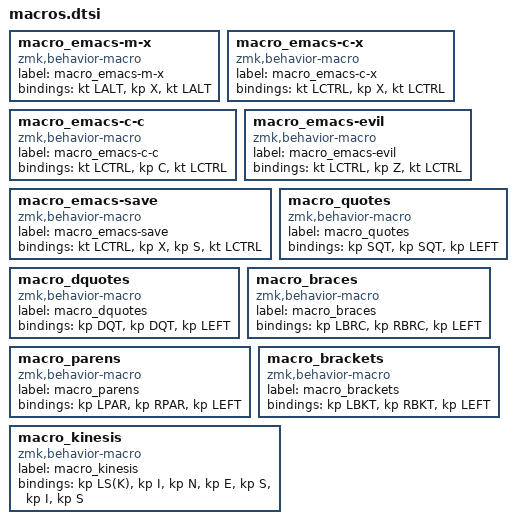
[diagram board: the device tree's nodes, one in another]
macro_emacs-m-x: macro_emacs-m-x{
compatible = "zmk,behavior-macro";
label = "macro_emacs-m-x";
#binding-cells = <0>;
bindings = <&kt LALT>, <&kp X>, <&kt LALT>;
};
macro_emacs-c-x: macro_emacs-c-x{
compatible = "zmk,behavior-macro";
label = "macro_emacs-c-x";
#binding-cells = <0>;
bindings = <&kt LCTRL>, <&kp X>, <&kt LCTRL>;
};
macro_emacs-c-c: macro_emacs-c-c{
compatible = "zmk,behavior-macro";
label = "macro_emacs-c-c";
#binding-cells = <0>;
bindings = <&kt LCTRL>, <&kp C>, <&kt LCTRL>;
};
macro_emacs-evil: macro_emacs-evil{
compatible = "zmk,behavior-macro";
label = "macro_emacs-evil";
#binding-cells = <0>;
bindings = <&kt LCTRL>, <&kp Z>, <&kt LCTRL>;
};
macro_emacs-save: macro_emacs-save{
compatible = "zmk,behavior-macro";
label = "macro_emacs-save";
#binding-cells = <0>;
bindings = <&kt LCTRL>, <&kp X>, <&kp S>, <&kt LCTRL>;
};
macro_quotes: macro_quotes{
compatible = "zmk,behavior-macro";
label = "macro_quotes";
#binding-cells = <0>;
bindings = <&kp SQT>, <&kp SQT>, <&kp LEFT>;
};
macro_dquotes: macro_dquotes{
compatible = "zmk,behavior-macro";
label = "macro_dquotes";
#binding-cells = <0>;
bindings = <&kp DQT>, <&kp DQT>, <&kp LEFT>;
};
macro_braces: macro_braces{
compatible = "zmk,behavior-macro";
label = "macro_braces";
#binding-cells = <0>;
bindings = <&kp LBRC>, <&kp RBRC>, <&kp LEFT>;
};
macro_parens: macro_parens{
compatible = "zmk,behavior-macro";
label = "macro_parens";
#binding-cells = <0>;
bindings = <&kp LPAR>, <&kp RPAR>, <&kp LEFT>;
};
macro_brackets: macro_brackets{
compatible = "zmk,behavior-macro";
label = "macro_brackets";
#binding-cells = <0>;
bindings = <&kp LBKT>, <&kp RBKT>, <&kp LEFT>;
};
macro_kinesis: macro_kinesis{
compatible = "zmk,behavior-macro";
label = "macro_kinesis";
#binding-cells = <0>;
bindings = <&kp LS(K)>, <&kp I>, <&kp N>, <&kp E>, <&kp S>, <&kp I>, <&kp S>;
};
